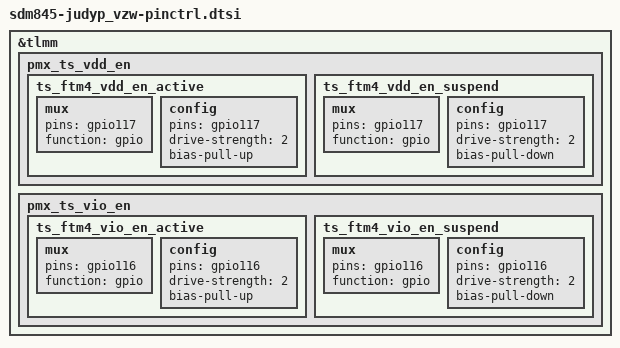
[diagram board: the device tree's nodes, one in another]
/* Copyright (c) 2017, The Linux Foundation. All rights reserved.
 *
 * This program is free software; you can redistribute it and/or modify
 * it under the terms of the GNU General Public License version 2 and
 * only version 2 as published by the Free Software Foundation.
 *
 * This program is distributed in the hope that it will be useful,
 * but WITHOUT ANY WARRANTY; without even the implied warranty of
 * MERCHANTABILITY or FITNESS FOR A PARTICULAR PURPOSE.  See the
 * GNU General Public License for more details.
 */

#include "../sdm845-judyp_common/sdm845-judyp_common-pinctrl.dtsi"

&tlmm {
	       pmx_ts_vdd_en {
			ts_ftm4_vdd_en_active: ts_ftm4_vdd_en_active {
				mux {
					pins = "gpio117";
					function = "gpio";
				};
				config {
					pins = "gpio117";
					drive-strength = <2>;
					bias-pull-up;
				};
			};

			ts_ftm4_vdd_en_suspend: ts_ftm4_vdd_en_suspend {
				mux {
					pins = "gpio117";
					function = "gpio";
				};
				config {
					pins = "gpio117";
					drive-strength = <2>;
					bias-pull-down;
				};
			};
		};

		pmx_ts_vio_en {
			ts_ftm4_vio_en_active: ts_ftm4_vio_en_active {
				mux {
					pins = "gpio116";
					function = "gpio";
				};
				config {
					pins = "gpio116";
					drive-strength = <2>;
					bias-pull-up;
				};
			};

			ts_ftm4_vio_en_suspend: ts_ftm4_vio_en_suspend {
				mux {
					pins = "gpio116";
					function = "gpio";
				};
				config {
					pins = "gpio116";
					drive-strength = <2>;
					bias-pull-down;
				};
			};
		};
};
